# YTM32B1MD2 register map
Vendor: YTMicro; File version: 1.0
CPU: CM33 r0p4, little endian, MPU, FPU, 2 interrupt priority bits
Registers are 32-bit, read-write, reset 0x0 unless marked. A register's access mark holds for its fields unless they carry their own. Offsets are from the block's base; [hi:lo] are bit positions; {n}, {i} and the like mark numbered series; 'fields as' and 'values as' point back to an identical list.

## HCU — Hardware Cryptography Unit
Base 0x40067000; register names take the prefix HCU_
0x00 GO
  [0] GO — Start Encryption/Decryption and indicate the module work state, write 0 to this bit is invalid.
    0=Encryption/Decryption idle; 1=Encryption/Decryption running
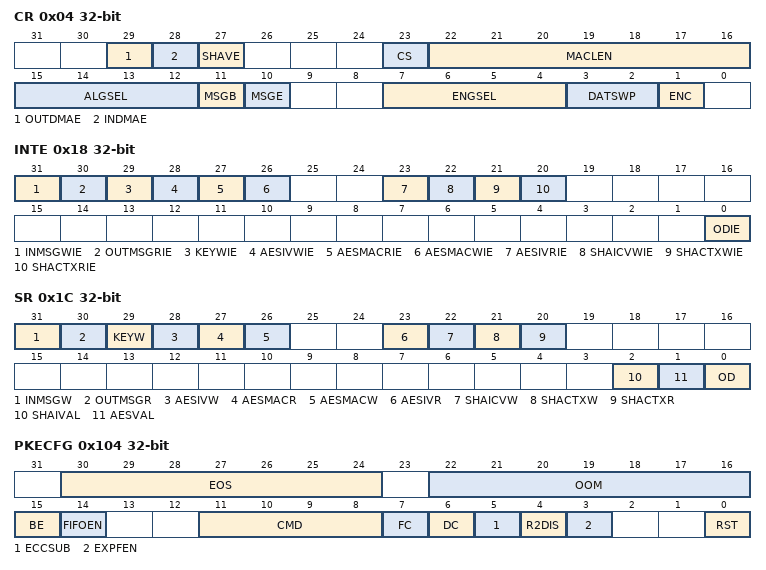
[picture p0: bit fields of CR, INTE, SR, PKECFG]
0x04 CR
  [29] OUTDMAE — Output message DMA enable/disable.
    0=Output message DMA is disabled; 1=Output message DMA is enabled
  [28] INDMAE — Input message DMA enable/disable.
    0=Input message dma is disabled; 1=Input message dma is enabled
  [27] SHAVE — SHA hash result verification enable/disable.
    0=SHA hash result verification is disable; 1=SHA hash result verification is enable
  [23] CS — Store the context data, for multiple message blocks process.
    0=Don't store context data; 1=Store context data
  [22:16] MACLEN — MAC bit length for generation or validation. Value 0 indicates the max length.
  [15:12] ALGSEL — Select algorithm for selected engine.
  [11] MSGB — Indicate the first message block, for multiple message blocks process.
    0=Current data block isn't the first block of the whole data; 1=Current data block is the first block of the whole data
  [10] MSGE — Indicate the last message block, for multiple message blocks process.
    0=Current data block isn't the last block of the whole data; 1=Current data block is the last block of the whole data
  [7:4] ENGSEL — Select engine for encryption/decryption.
    0=disable; 1=AES; 3=SHA; 4=PKE
  [3:2] DATSWP — Select the type of data swapping.
    0=No swapping; 1=Half-word swapping; 2=Byte swapping; 3=Bit swapping
  [1] ENC — Select encryption or decryption mode.
    0=Decryption; 1=Encryption
0x08 MSGINFO
  [27:0] MSGTOT — Indicate byte number of message in total.
0x0C MSGCUR
  [15:0] MSGLEN — Indicate byte number of message in current block.
0x18 INTE
  [31] INMSGWIE — Input message wait interrupt enable/disable.
    0=Input message wait interrupt disable; 1=Input message wait interrupt enable
  [30] OUTMSGRIE — Output message ready interrupt enable/disable.
    0=Output message ready interrupt disable; 1=Output message ready interrupt enable
  [29] KEYWIE — Key wait interrupt enable/disable.
    0=Key wait interrupt disable; 1=Key wait interrupt enable
  [28] AESIVWIE — AES initial vector wait interrupt enable/disable.
    0=AES initial vector wait interrupt disable; 1=AES initial vector wait interrupt enable
  [27] AESMACRIE — AES MAC ready interrupt enable/disable.
    0=AES MAC ready interrupt disable; 1=AES MAC ready interrupt enable
  [26] AESMACWIE — AES MAC wait interrupt enable/disable.
    0=AES MAC wait interrupt disable; 1=AES MAC wait interrupt enable
  [23] AESIVRIE — AES initial vector ready interrupt enable/disable.
    0=AES initial vector ready interrupt disable; 1=AES initial vector ready interrupt enable
  [22] SHAICVWIE — SHA icv wait interrupt enable/disable.
    0=SHA icv wait interrupt disable; 1=SHA icv wait interrupt enable
  [21] SHACTXWIE — SHA context data wait interrupt enable/disable.
    0=SHA context data wait interrupt disable; 1=SHA context data wait interrupt enable
  [20] SHACTXRIE — SHA context data ready interrupt enable/disable.
    0=SHA context data ready interrupt disable; 1=SHA context data ready interrupt enable
  [0] ODIE — Operation done interrupt enable/disable.
    0=Operation done interrupt disable; 1=Operation done interrupt enable
0x1C SR
  [31] INMSGW ro — Input message wait flag.
    0=Don't care; 1=HCU is waiting for input message. Need write INMSG register.
  [30] OUTMSGR ro — Output message ready flag.
    0=Don't care; 1=Output message is ready for reading. Need read OUTMSG register.
  [29] KEYW ro — Key wait flag.
    0=Don't care; 1=HCU is waiting for key. Need write KEY registers or execute load key value EFM command.
  [28] AESIVW ro — AES initial vector wait flag.
    0=Don't care; 1=HCU is waiting for AES initial vector. Need write CONTEXT_4_7 registers.
  [27] AESMACR ro — AES MAC ready flag.
    0=Don't care; 1=AES MAC is ready for reading. Need read CONTEXT_8_11 registers.
  [26] AESMACW ro — AES MAC wait flag.
    0=Don't care; 1=HCU is waiting for AES MAC. Need write CONTEXT_8_11 registers.
  [23] AESIVR ro — AES initial vector ready flag.
    0=Don't care; 1=AES initial vector is ready for reading. Need read CONTEXT_4_7 registers.
  [22] SHAICVW — SHA icv wait flag.
    0=Don't care; 1=HCU is waiting for SHA icv
  [21] SHACTXW — SHA context data wait flag.
    0=Don't care; 1=HCU is waiting for SHA context data
  [20] SHACTXR — SHA context data ready flag.
    0=Don't care; 1=SHA context data is ready for reading
  [2] SHAIVAL ro — Indicate the verify result of input hash value.
    0=Input hash value is equal to the calculate result; 1=Input hash value is not equal to the calculate result
  [1] AESVAL ro — Indicate AES MAC validation result.
    0=The input MAC is not equal to the calculate result; 1=The input MAC is equal to the calculate result
  [0] OD — Indicate Encryption/Decryption operation state. Write 1 to clear this bit.
    0=Operation doesn't begin or under running; 1=Operation done
0x20 INMSG wo
  [31:0] INMSG rw — Input message, write data that to be encrypted/decrypted.
0x24 OUTMSG ro
  [31:0] OUTMSG rw — Output message, read data that after encryption/decryption.
{0x30+4i} KEY{i} wo (i=0..3)
  [31:0] KEY rw — Key value for Encryption/Decryption.
0x60 CONTEXT_4_70
  [31:0] CONTEXT — Initial vector value for AES Encryption/Decryption.
0x64 CONTEXT_4_71
  [31:0] CONTEXT — Initial vector value for AES Encryption/Decryption.
0x68 CONTEXT_4_72
  [31:0] CONTEXT — Initial vector value for AES Encryption/Decryption.
0x6C CONTEXT_4_73
  [31:0] CONTEXT — Initial vector value for AES Encryption/Decryption.
0x70 CONTEXT_8_110
  [31:0] CONTEXT — MAC value generated in AES Encryption or write for AES Decryption.
0x74 CONTEXT_8_111
  fields as CONTEXT_8_110
0x78 CONTEXT_8_112
  fields as CONTEXT_8_110
0x7C CONTEXT_8_113
  fields as CONTEXT_8_110
0x80 CONTEXT_12_190
  [31:0] CONTEXT — SHA icv for verification.
0x84 CONTEXT_12_191
  [31:0] CONTEXT — SHA icv for verification.
0x88 CONTEXT_12_192
  [31:0] CONTEXT — SHA icv for verification.
0x8C CONTEXT_12_193
  [31:0] CONTEXT — SHA icv for verification.
0x90 CONTEXT_12_194
  [31:0] CONTEXT — SHA icv for verification.
0x94 CONTEXT_12_195
  [31:0] CONTEXT — SHA icv for verification.
0x98 CONTEXT_12_196
  [31:0] CONTEXT — SHA icv for verification.
0x9C CONTEXT_12_197
  [31:0] CONTEXT — SHA icv for verification.
0xC0 CONTEXT_28_350
  [31:0] CONTEXT — SHA context data for message break.
0xC4 CONTEXT_28_351
  [31:0] CONTEXT — SHA context data for message break.
0xC8 CONTEXT_28_352
  [31:0] CONTEXT — SHA context data for message break.
0xCC CONTEXT_28_353
  [31:0] CONTEXT — SHA context data for message break.
0xD0 CONTEXT_28_354
  [31:0] CONTEXT — SHA context data for message break.
0xD4 CONTEXT_28_355
  [31:0] CONTEXT — SHA context data for message break.
0xD8 CONTEXT_28_356
  [31:0] CONTEXT — SHA context data for message break.
0xDC CONTEXT_28_357
  [31:0] CONTEXT — SHA context data for message break.
0x100 PKEST
  [0] ST — Start calculation. This bit clear by itself.
    0=No effect; 1=The PKE starts to work
0x104 PKECFG
  [30:24] EOS — The E size. The EOS must match the actual valid length of E.
  [22:16] OOM — The operation mode. The OOM must match the actual valid length of N.
  [15] BE — The bit indicates the input operand and output result data endian format.
    0=The PKE input operand is little-endian; 1=The PKE input operand is big-endian
  [14] FIFOEN — The PKE operation in fifo mode.
    0=The PKE operation is in normal mode; 1=The PKE operation is in fifo mode
  [11:8] CMD — The PKE command operation.
  [7] FC — The bit control false multiply and square operation according to attacking algorithm in expf operation.
    0=No effect; 1=The PKE executes false operation
  [6] DC — The bit control dummy multiply operation according to attacking algorithm in expf operation.
    0=No effect; 1=The PKE executes dummy operation
  [5] ECCSUB — Select ECC calculation mode.
    0=The add operation selection in ECC calculations; 1=The sub operation selection in ECC calculation
  [4] R2DIS — The RSA doesn't calculate R2 mod N in pre-calculate.
    0=The RSA need calculate R2 mod N; 1=The RSA doesn't need calculate R2 mod N
  [3] EXPFEN — The PKE operates in expf command or not. Only enable this bit when CMD=0,2,5 in RSA calculation or CMD=2 in ECC calculation.
    0=The PKE do not operate in expf command; 1=The PKE operates in expf command
  [0] RST — The PKE reset control signal. This bit clear by itself.
    0=No effect; 1=The PKE resets its inner register
0x108 PKEIE
  [0] IE — The PKE interrupt enable.
    0=The PKE interrupt disable; 1=The PKE interrupt enable
0x10C PKESTAT
  [0] DONE — The PKE operation finished. Write 1 to clear this bit.
    0=The PKE operation is going or not start; 1=The PKE operation finished
{0x110+4i} PKEA{i} (i=0..127)
  [31:0] A — Input the lowest word from the lowest offset address. Half word and byte size access to this register is not allowed and may result in undefined behavior. The value of A must be less than N.
{0x310+4i} PKEE{i} (i=0..127)
  [31:0] E — Input the lowest word from the lowest offset address. Half word and byte size access to this register is not allowed and may result in undefined behavior. The value of E must be less than N.
{0x510+4i} PKEN{i} (i=0..127)
  [31:0] N — Input the lowest word from the lowest offset address. Half word and byte size access to this register is not allowed and may result in undefined behavior.
0x710 PKEAF — Before write data into FIFO or read data out from FIFO, please set a correct index by PKEFCNT[FCNT].
  [31:0] A — Input data from the lowest word to the highest word, the input length is depended on the value of the PKEC[OOM] field. Half word and byte size access to this register is not allowed and may result in undefined behavior. The value of A must be less than N.
0x714 PKEEF — Before write data into FIFO or read data out from FIFO, please set a correct index by PKEFCNT[FCNT].
  [31:0] E — Input data from the lowest word to the highest word, the input length is depended on the value of the PKEC[OOM] field. Half word and byte size access to this register is not allowed and may result in undefined behavior. The value of E must be less than N.
0x718 PKENF — Before write data into FIFO or read data out from FIFO, please set a correct index by PKEFCNT[FCNT].
  [31:0] N — Input data from the lowest word to the highest word, the input length is depended on the value of the PKEC[OOM] field. Half word and byte size access to this register is not allowed and may result in undefined behavior.
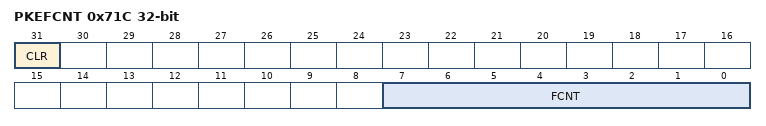
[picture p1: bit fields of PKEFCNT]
0x71C PKEFCNT
  [31] CLR wo — Clear fifo count value. Write 1 to clear FCNT.
  [7:0] FCNT — The register is used to count the length of A/E/N operand in FIFO mode. Clear this field before storing A/E/N operand.
